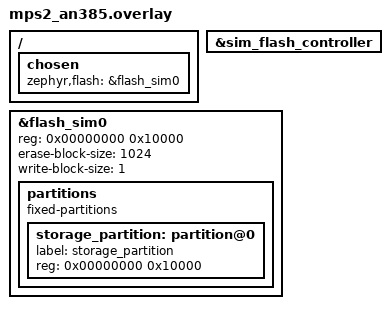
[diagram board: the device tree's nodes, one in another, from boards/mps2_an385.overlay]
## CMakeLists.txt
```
# Zephyr CMakeLists.txt for littlefs ztest
cmake_minimum_required(VERSION 3.20.0)
find_package(Zephyr REQUIRED HINTS $ENV{ZEPHYR_BASE})
project(littlefs_test)

# littlefs core library
target_sources(app PRIVATE
    ../lfs.c
    ../lfs_util.c
)

# Zephyr flash block device wrapper
target_sources(app PRIVATE
    src/lfs_test_bd_zephyr.c
)

# Test sources
target_sources(app PRIVATE
    src/main.c
    src/test_superblocks.c
    src/test_files.c
    src/test_dirs.c
    src/test_paths.c
    src/test_seek.c
    src/test_move.c
    src/test_truncate.c
    src/test_alloc.c
    src/test_attrs.c
    src/test_entries.c
)

target_include_directories(app PRIVATE
    ${CMAKE_CURRENT_SOURCE_DIR}/..
    ${CMAKE_CURRENT_SOURCE_DIR}/../test
)

# Disable littlefs assertions for ztest (they cause kernel panics)
# Use zassert instead for test assertions
target_compile_definitions(app PRIVATE
    LFS_NO_ASSERT
)
```

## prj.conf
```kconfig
# Ztest framework
CONFIG_ZTEST=y

# Size optimization
CONFIG_SIZE_OPTIMIZATIONS=y
CONFIG_LOG=n

# Flash subsystem
CONFIG_FLASH=y
CONFIG_FLASH_SIMULATOR=y
CONFIG_FLASH_SIMULATOR_DOUBLE_WRITES=y
CONFIG_FLASH_SIMULATOR_STATS=n

# Memory (increased for full test suite)
CONFIG_HEAP_MEM_POOL_SIZE=32768
CONFIG_MAIN_STACK_SIZE=8192
```

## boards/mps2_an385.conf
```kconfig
# Board-specific configuration for mps2_an385
# Increase code partition to 512KB
CONFIG_FLASH_SIZE=512
```

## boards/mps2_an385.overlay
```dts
/*
 * Flash simulator overlay for MPS2_AN385
 * Uses the built-in flash simulator for littlefs testing
 */

/ {
	chosen {
		/* Point to simulated flash instead of main flash */
		zephyr,flash = &flash_sim0;
	};
};

/* Enable the flash controller */
&sim_flash_controller {
	status = "okay";
};

/* Override flash_sim0 to have more blocks for testing */
&flash_sim0 {
	status = "okay";
	reg = <0x00000000 0x10000>;  /* 64KB simulated flash */
	erase-block-size = <1024>;
	write-block-size = <1>;

	partitions {
		compatible = "fixed-partitions";
		#address-cells = <1>;
		#size-cells = <1>;

		storage_partition: partition@0 {
			label = "storage_partition";
			reg = <0x00000000 0x10000>;
		};
	};
};
```

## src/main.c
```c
/*
 * littlefs ztest - Block device tests
 *
 * These tests validate that the underlying block device is working correctly.
 * Note: We use 251, a prime, to avoid aliasing powers of 2.
 */
#define LFS_TEST_ZTEST

#include <zephyr/ztest.h>
#include <stdbool.h>
#include <string.h>

#include "lfs.h"
#include "test/lfs_test_bd.h"

/* Shared globals for all test suites */
struct lfs_test_bd ztest_bd;
struct lfs_config ztest_cfg;
bool ztest_bd_initialized = false;

/* Local aliases for bd_tests */
#define bd ztest_bd
#define cfg ztest_cfg

static void *bd_suite_setup(void)
{
    int ret = lfs_test_bd_create(&bd, &cfg, &lfs_test_geometries[0]);
    zassert_equal(ret, 0, "Failed to create block device");
    return NULL;
}

static void bd_suite_teardown(void *f)
{
    ARG_UNUSED(f);
    lfs_test_bd_destroy(&bd, &cfg);
}

static void bd_before_each(void *f)
{
    ARG_UNUSED(f);
    /* Erase entire device before each test for clean state */
    for (lfs_block_t i = 0; i < cfg.block_count; i++) {
        int ret = cfg.erase(&cfg, i);
        zassert_equal(ret, 0, "Failed to erase block %u", i);
    }
}

ZTEST_SUITE(bd_tests, NULL, bd_suite_setup, bd_before_each, NULL, bd_suite_teardown);

/*
 * Test: Write and read a single block
 */
ZTEST(bd_tests, test_one_block)
{
    lfs_size_t read_size = cfg.read_size;
    lfs_size_t prog_size = cfg.prog_size;
    uint8_t buffer[prog_size > read_size ? prog_size : read_size];

    /* Write data */
    zassert_equal(cfg.erase(&cfg, 0), 0, "Erase failed");
    for (lfs_off_t i = 0; i < cfg.block_size; i += prog_size) {
        for (lfs_off_t j = 0; j < prog_size; j++) {
            buffer[j] = (i + j) % 251;
        }
        zassert_equal(cfg.prog(&cfg, 0, i, buffer, prog_size), 0,
                      "Prog failed at offset %u", i);
    }

    /* Read data */
    for (lfs_off_t i = 0; i < cfg.block_size; i += read_size) {
        zassert_equal(cfg.read(&cfg, 0, i, buffer, read_size), 0,
                      "Read failed at offset %u", i);
        for (lfs_off_t j = 0; j < read_size; j++) {
            zassert_equal(buffer[j], (i + j) % 251,
                          "Mismatch at offset %u", i + j);
        }
    }
}

/*
 * Test: Write and read two blocks, verify no interference
 */
ZTEST(bd_tests, test_two_block)
{
    lfs_size_t read_size = cfg.read_size;
    lfs_size_t prog_size = cfg.prog_size;
    uint8_t buffer[prog_size > read_size ? prog_size : read_size];
    lfs_block_t block;

    /* Write block 0 */
    block = 0;
    zassert_equal(cfg.erase(&cfg, block), 0, "Erase failed");
    for (lfs_off_t i = 0; i < cfg.block_size; i += prog_size) {
        for (lfs_off_t j = 0; j < prog_size; j++) {
            buffer[j] = (block + i + j) % 251;
        }
        zassert_equal(cfg.prog(&cfg, block, i, buffer, prog_size), 0,
                      "Prog failed");
    }

    /* Read block 0 */
    for (lfs_off_t i = 0; i < cfg.block_size; i += read_size) {
        zassert_equal(cfg.read(&cfg, block, i, buffer, read_size), 0,
                      "Read failed");
        for (lfs_off_t j = 0; j < read_size; j++) {
            zassert_equal(buffer[j], (block + i + j) % 251,
                          "Mismatch at offset %u", i + j);
        }
    }

    /* Write block 1 */
    block = 1;
    zassert_equal(cfg.erase(&cfg, block), 0, "Erase failed");
    for (lfs_off_t i = 0; i < cfg.block_size; i += prog_size) {
        for (lfs_off_t j = 0; j < prog_size; j++) {
            buffer[j] = (block + i + j) % 251;
        }
        zassert_equal(cfg.prog(&cfg, block, i, buffer, prog_size), 0,
                      "Prog failed");
    }

    /* Read block 1 */
    for (lfs_off_t i = 0; i < cfg.block_size; i += read_size) {
        zassert_equal(cfg.read(&cfg, block, i, buffer, read_size), 0,
                      "Read failed");
        for (lfs_off_t j = 0; j < read_size; j++) {
            zassert_equal(buffer[j], (block + i + j) % 251,
                          "Mismatch at offset %u", i + j);
        }
    }

    /* Read block 0 again - verify not corrupted */
    block = 0;
    for (lfs_off_t i = 0; i < cfg.block_size; i += read_size) {
        zassert_equal(cfg.read(&cfg, block, i, buffer, read_size), 0,
                      "Read failed");
        for (lfs_off_t j = 0; j < read_size; j++) {
            zassert_equal(buffer[j], (block + i + j) % 251,
                          "Block 0 was corrupted");
        }
    }
}

/*
 * Test: Write first and last blocks
 */
ZTEST(bd_tests, test_last_block)
{
    lfs_size_t read_size = cfg.read_size;
    lfs_size_t prog_size = cfg.prog_size;
    uint8_t buffer[prog_size > read_size ? prog_size : read_size];
    lfs_block_t block;

    /* Write block 0 */
    block = 0;
    zassert_equal(cfg.erase(&cfg, block), 0, "Erase failed");
    for (lfs_off_t i = 0; i < cfg.block_size; i += prog_size) {
        for (lfs_off_t j = 0; j < prog_size; j++) {
            buffer[j] = (block + i + j) % 251;
        }
        zassert_equal(cfg.prog(&cfg, block, i, buffer, prog_size), 0,
                      "Prog failed");
    }

    /* Write block n-1 */
    block = cfg.block_count - 1;
    zassert_equal(cfg.erase(&cfg, block), 0, "Erase failed");
    for (lfs_off_t i = 0; i < cfg.block_size; i += prog_size) {
        for (lfs_off_t j = 0; j < prog_size; j++) {
            buffer[j] = (block + i + j) % 251;
        }
        zassert_equal(cfg.prog(&cfg, block, i, buffer, prog_size), 0,
                      "Prog failed");
    }

    /* Read block 0 */
    block = 0;
    for (lfs_off_t i = 0; i < cfg.block_size; i += read_size) {
        zassert_equal(cfg.read(&cfg, block, i, buffer, read_size), 0,
                      "Read failed");
        for (lfs_off_t j = 0; j < read_size; j++) {
            zassert_equal(buffer[j], (block + i + j) % 251,
                          "Mismatch");
        }
    }

    /* Read block n-1 */
    block = cfg.block_count - 1;
    for (lfs_off_t i = 0; i < cfg.block_size; i += read_size) {
        zassert_equal(cfg.read(&cfg, block, i, buffer, read_size), 0,
                      "Read failed");
        for (lfs_off_t j = 0; j < read_size; j++) {
            zassert_equal(buffer[j], (block + i + j) % 251,
                          "Mismatch");
        }
    }
}

/*
 * Test: Write and read blocks at powers of two
 */
ZTEST(bd_tests, test_powers_of_two)
{
    lfs_size_t read_size = cfg.read_size;
    lfs_size_t prog_size = cfg.prog_size;
    uint8_t buffer[prog_size > read_size ? prog_size : read_size];

    /* Write/read every power of 2 */
    lfs_block_t block = 1;
    while (block < cfg.block_count) {
        /* Write */
        zassert_equal(cfg.erase(&cfg, block), 0, "Erase failed");
        for (lfs_off_t i = 0; i < cfg.block_size; i += prog_size) {
            for (lfs_off_t j = 0; j < prog_size; j++) {
                buffer[j] = (block + i + j) % 251;
            }
            zassert_equal(cfg.prog(&cfg, block, i, buffer, prog_size), 0,
                          "Prog failed");
        }

        /* Read */
        for (lfs_off_t i = 0; i < cfg.block_size; i += read_size) {
            zassert_equal(cfg.read(&cfg, block, i, buffer, read_size), 0,
                          "Read failed");
            for (lfs_off_t j = 0; j < read_size; j++) {
                zassert_equal(buffer[j], (block + i + j) % 251,
                              "Mismatch at block %u", block);
            }
        }

        block *= 2;
    }
}

/*
 * Test: Write and read blocks at Fibonacci numbers
 */
ZTEST(bd_tests, test_fibonacci)
{
    lfs_size_t read_size = cfg.read_size;
    lfs_size_t prog_size = cfg.prog_size;
    uint8_t buffer[prog_size > read_size ? prog_size : read_size];

    /* Write/read every Fibonacci number */
    lfs_block_t block = 1;
    lfs_block_t block_prev = 1;
    while (block < cfg.block_count) {
        /* Write */
        zassert_equal(cfg.erase(&cfg, block), 0, "Erase failed");
        for (lfs_off_t i = 0; i < cfg.block_size; i += prog_size) {
            for (lfs_off_t j = 0; j < prog_size; j++) {
                buffer[j] = (block + i + j) % 251;
            }
            zassert_equal(cfg.prog(&cfg, block, i, buffer, prog_size), 0,
                          "Prog failed");
        }

        /* Read */
        for (lfs_off_t i = 0; i < cfg.block_size; i += read_size) {
            zassert_equal(cfg.read(&cfg, block, i, buffer, read_size), 0,
                          "Read failed");
            for (lfs_off_t j = 0; j < read_size; j++) {
                zassert_equal(buffer[j], (block + i + j) % 251,
                              "Mismatch at block %u", block);
            }
        }

        lfs_block_t next = block + block_prev;
        block_prev = block;
        block = next;
    }
}
```

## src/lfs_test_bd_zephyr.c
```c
/*
 * Block device implementation using Zephyr flash API
 */
#define LFS_TEST_ZTEST

#include <zephyr/kernel.h>
#include <zephyr/device.h>
#include <zephyr/drivers/flash.h>
#include <string.h>

#include "lfs.h"
#include "test/lfs_test_bd.h"

/* Standard geometries - use smaller values for constrained memory
 * qemu_cortex_m3 has 256KB flash, we use a portion of it
 */
const struct lfs_test_geometry lfs_test_geometries[] = {
    /* 1KB erase size, 64 blocks = 64KB total (MPS2 flash simulator) */
    {"qemu", 1, 1, 1024, 64},
};

const size_t lfs_test_geometry_count =
    sizeof(lfs_test_geometries) / sizeof(lfs_test_geometries[0]);

static int zephyr_read(const struct lfs_config *c, lfs_block_t block,
                       lfs_off_t off, void *buffer, lfs_size_t size) {
    struct lfs_test_bd *bd = c->context;
    off_t addr = bd->offset + block * c->block_size + off;

    int ret = flash_read(bd->flash_dev, addr, buffer, size);
    return ret < 0 ? LFS_ERR_IO : 0;
}

static int zephyr_prog(const struct lfs_config *c, lfs_block_t block,
                       lfs_off_t off, const void *buffer, lfs_size_t size) {
    struct lfs_test_bd *bd = c->context;
    off_t addr = bd->offset + block * c->block_size + off;

    int ret = flash_write(bd->flash_dev, addr, buffer, size);
    return ret < 0 ? LFS_ERR_IO : 0;
}

static int zephyr_erase(const struct lfs_config *c, lfs_block_t block) {
    struct lfs_test_bd *bd = c->context;
    off_t addr = bd->offset + block * c->block_size;

    int ret = flash_erase(bd->flash_dev, addr, c->block_size);
    return ret < 0 ? LFS_ERR_IO : 0;
}

static int zephyr_sync(const struct lfs_config *c) {
    ARG_UNUSED(c);
    return 0;
}

int lfs_test_bd_create(struct lfs_test_bd *bd,
                       struct lfs_config *cfg,
                       const struct lfs_test_geometry *geom) {
    memset(bd, 0, sizeof(*bd));

    /* Use simulated flash controller device */
    bd->flash_dev = DEVICE_DT_GET(DT_CHOSEN(zephyr_flash_controller));
    bd->offset = 0;  /* Simulated flash - full device available */
    bd->size = geom->erase_size * geom->erase_count;

    if (!device_is_ready(bd->flash_dev)) {
        return LFS_ERR_IO;
    }

    /* Initialize lfs config */
    memset(cfg, 0, sizeof(*cfg));
    cfg->context = bd;
    cfg->read = zephyr_read;
    cfg->prog = zephyr_prog;
    cfg->erase = zephyr_erase;
    cfg->sync = zephyr_sync;
    cfg->read_size = geom->read_size;
    cfg->prog_size = geom->prog_size;
    cfg->block_size = geom->erase_size;
    cfg->block_count = geom->erase_count;
    cfg->block_cycles = -1;
    cfg->cache_size = 64;
    cfg->lookahead_size = 16;

    return 0;
}

int lfs_test_bd_destroy(struct lfs_test_bd *bd,
                        struct lfs_config *cfg) {
    ARG_UNUSED(bd);
    ARG_UNUSED(cfg);
    return 0;
}
```

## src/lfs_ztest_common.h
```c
/*
 * Common test infrastructure for littlefs ztest
 */
#ifndef LFS_ZTEST_COMMON_H
#define LFS_ZTEST_COMMON_H

#include <zephyr/ztest.h>
#include <string.h>

#include "lfs.h"
#include "test/lfs_test_bd.h"

/* Shared block device and config */
extern struct lfs_test_bd ztest_bd;
extern struct lfs_config ztest_cfg;
extern bool ztest_bd_initialized;

/* Initialize the block device if not already done */
static inline void lfs_ztest_init_device(void)
{
    if (!ztest_bd_initialized) {
        int ret = lfs_test_bd_create(&ztest_bd, &ztest_cfg, &lfs_test_geometries[0]);
        zassert_equal(ret, 0, "Failed to create block device");
        ztest_bd_initialized = true;
    }
}

/* Helper to erase the filesystem before test */
static inline void lfs_ztest_format_device(void)
{
    lfs_ztest_init_device();
    /* Erase entire device for clean state */
    for (lfs_block_t i = 0; i < ztest_cfg.block_count; i++) {
        int ret = ztest_cfg.erase(&ztest_cfg, i);
        zassert_equal(ret, 0, "Failed to erase block %u", i);
    }
}

/* Simple PRNG for test data generation */
static inline uint32_t lfs_ztest_prng(uint32_t *state)
{
    *state = *state * 1103515245 + 12345;
    return *state;
}

#endif /* LFS_ZTEST_COMMON_H */
```

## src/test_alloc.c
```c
/*
 * Block allocation tests
 */
#include "lfs_ztest_common.h"
#include <stdio.h>

static void *alloc_setup(void)
{
    lfs_ztest_format_device();
    return NULL;
}

static void alloc_before(void *f)
{
    ARG_UNUSED(f);
    lfs_ztest_format_device();
}

ZTEST_SUITE(alloc_tests, NULL, alloc_setup, alloc_before, NULL, NULL);

/* Parallel allocation - create many files without closing */
ZTEST(alloc_tests, test_parallel_alloc)
{
    lfs_t lfs;
    zassert_equal(lfs_format(&lfs, &ztest_cfg), 0, "Format failed");
    zassert_equal(lfs_mount(&lfs, &ztest_cfg), 0, "Mount failed");

    const int N = 3;  /* Limited by open file handles */
    lfs_file_t files[3];

    /* Open multiple files at once */
    for (int i = 0; i < N; i++) {
        char name[32];
        snprintf(name, sizeof(name), "parallel%d", i);
        zassert_equal(lfs_file_open(&lfs, &files[i], name,
                LFS_O_WRONLY | LFS_O_CREAT | LFS_O_EXCL), 0,
                "Open %d failed", i);
    }

    /* Write to all of them */
    for (int i = 0; i < N; i++) {
        char data[32];
        snprintf(data, sizeof(data), "data%d", i);
        zassert_equal(lfs_file_write(&lfs, &files[i], data, strlen(data)),
                      (lfs_ssize_t)strlen(data), "Write %d failed", i);
    }

    /* Close all */
    for (int i = 0; i < N; i++) {
        zassert_equal(lfs_file_close(&lfs, &files[i]), 0, "Close %d failed", i);
    }

    zassert_equal(lfs_unmount(&lfs), 0, "Unmount failed");

    /* Verify */
    zassert_equal(lfs_mount(&lfs, &ztest_cfg), 0, "Remount failed");
    for (int i = 0; i < N; i++) {
        char name[32], expected[32], buffer[32];
        snprintf(name, sizeof(name), "parallel%d", i);
        snprintf(expected, sizeof(expected), "data%d", i);
        lfs_file_t file;
        zassert_equal(lfs_file_open(&lfs, &file, name, LFS_O_RDONLY), 0,
                      "Reopen %d failed", i);
        int len = lfs_file_read(&lfs, &file, buffer, sizeof(buffer));
        zassert_equal(len, (int)strlen(expected), "Read %d size wrong", i);
        buffer[len] = '\0';
        zassert_equal(strcmp(buffer, expected), 0, "Data %d mismatch", i);
        zassert_equal(lfs_file_close(&lfs, &file), 0, "Close %d failed", i);
    }
    zassert_equal(lfs_unmount(&lfs), 0, "Unmount failed");
}

/* Serial allocation - create and close files sequentially */
ZTEST(alloc_tests, test_serial_alloc)
{
    lfs_t lfs;
    zassert_equal(lfs_format(&lfs, &ztest_cfg), 0, "Format failed");
    zassert_equal(lfs_mount(&lfs, &ztest_cfg), 0, "Mount failed");

    const int N = 10;
    for (int i = 0; i < N; i++) {
        char name[32], data[32];
        snprintf(name, sizeof(name), "serial%d", i);
        snprintf(data, sizeof(data), "serial_data_%d", i);

        lfs_file_t file;
        zassert_equal(lfs_file_open(&lfs, &file, name,
                LFS_O_WRONLY | LFS_O_CREAT | LFS_O_EXCL), 0,
                "Open %d failed", i);
        zassert_equal(lfs_file_write(&lfs, &file, data, strlen(data)),
                      (lfs_ssize_t)strlen(data), "Write %d failed", i);
        zassert_equal(lfs_file_close(&lfs, &file), 0, "Close %d failed", i);
    }

    zassert_equal(lfs_unmount(&lfs), 0, "Unmount failed");

    /* Verify */
    zassert_equal(lfs_mount(&lfs, &ztest_cfg), 0, "Remount failed");
    for (int i = 0; i < N; i++) {
        char name[32], expected[32], buffer[64];
        snprintf(name, sizeof(name), "serial%d", i);
        snprintf(expected, sizeof(expected), "serial_data_%d", i);

        lfs_file_t file;
        zassert_equal(lfs_file_open(&lfs, &file, name, LFS_O_RDONLY), 0,
                      "Reopen %d failed", i);
        int len = lfs_file_read(&lfs, &file, buffer, sizeof(buffer));
        zassert_equal(len, (int)strlen(expected), "Read %d size wrong", i);
        buffer[len] = '\0';
        zassert_equal(strcmp(buffer, expected), 0, "Data %d mismatch", i);
        zassert_equal(lfs_file_close(&lfs, &file), 0, "Close %d failed", i);
    }
    zassert_equal(lfs_unmount(&lfs), 0, "Unmount failed");
}

/*
 * NOTE: Exhaustion test removed - the Zephyr flash simulator hits internal
 * assertions when trying to fill the filesystem completely. This test
 * requires the emubd which tracks wear properly. Test coverage for
 * exhaustion is provided by gtest with emubd.
 */
```

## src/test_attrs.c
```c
/*
 * Extended attributes tests
 */
#include "lfs_ztest_common.h"

static void *attrs_setup(void)
{
    lfs_ztest_format_device();
    return NULL;
}

static void attrs_before(void *f)
{
    ARG_UNUSED(f);
    lfs_ztest_format_device();
}

ZTEST_SUITE(attrs_tests, NULL, attrs_setup, attrs_before, NULL, NULL);

/* Get/set attributes */
ZTEST(attrs_tests, test_getset)
{
    lfs_t lfs;
    zassert_equal(lfs_format(&lfs, &ztest_cfg), 0, "Format failed");
    zassert_equal(lfs_mount(&lfs, &ztest_cfg), 0, "Mount failed");

    /* Create a file */
    lfs_file_t file;
    zassert_equal(lfs_file_open(&lfs, &file, "attrfile",
            LFS_O_WRONLY | LFS_O_CREAT | LFS_O_EXCL), 0, "Open failed");
    zassert_equal(lfs_file_write(&lfs, &file, "test", 4), 4, "Write failed");
    zassert_equal(lfs_file_close(&lfs, &file), 0, "Close failed");

    /* Set attribute */
    const char *attrdata = "myattr";
    zassert_equal(lfs_setattr(&lfs, "attrfile", 'A', attrdata, strlen(attrdata)), 0,
                  "Setattr failed");

    /* Get attribute */
    char buffer[32];
    lfs_ssize_t len = lfs_getattr(&lfs, "attrfile", 'A', buffer, sizeof(buffer));
    zassert_equal(len, (lfs_ssize_t)strlen(attrdata), "Getattr size wrong");
    zassert_equal(memcmp(buffer, attrdata, len), 0, "Attr data mismatch");

    zassert_equal(lfs_unmount(&lfs), 0, "Unmount failed");

    /* Verify persists across mount */
    zassert_equal(lfs_mount(&lfs, &ztest_cfg), 0, "Remount failed");
    len = lfs_getattr(&lfs, "attrfile", 'A', buffer, sizeof(buffer));
    zassert_equal(len, (lfs_ssize_t)strlen(attrdata), "Getattr2 size wrong");
    zassert_equal(memcmp(buffer, attrdata, len), 0, "Attr2 data mismatch");
    zassert_equal(lfs_unmount(&lfs), 0, "Unmount failed");
}

/* Root attributes */
ZTEST(attrs_tests, test_root_attrs)
{
    lfs_t lfs;
    zassert_equal(lfs_format(&lfs, &ztest_cfg), 0, "Format failed");
    zassert_equal(lfs_mount(&lfs, &ztest_cfg), 0, "Mount failed");

    /* Set attribute on root */
    const char *rootattr = "rootdata";
    zassert_equal(lfs_setattr(&lfs, "/", 'R', rootattr, strlen(rootattr)), 0,
                  "Setattr root failed");

    /* Get it back */
    char buffer[32];
    lfs_ssize_t len = lfs_getattr(&lfs, "/", 'R', buffer, sizeof(buffer));
    zassert_equal(len, (lfs_ssize_t)strlen(rootattr), "Getattr size wrong");
    zassert_equal(memcmp(buffer, rootattr, len), 0, "Root attr mismatch");

    /* Also try "." */
    len = lfs_getattr(&lfs, ".", 'R', buffer, sizeof(buffer));
    zassert_equal(len, (lfs_ssize_t)strlen(rootattr), "Getattr . size wrong");

    zassert_equal(lfs_unmount(&lfs), 0, "Unmount failed");
}

/* File config with attributes */
ZTEST(attrs_tests, test_file_config)
{
    lfs_t lfs;
    zassert_equal(lfs_format(&lfs, &ztest_cfg), 0, "Format failed");
    zassert_equal(lfs_mount(&lfs, &ztest_cfg), 0, "Mount failed");

    /* Open file with attribute in config */
    uint8_t attr_buffer[64];
    memset(attr_buffer, 0, sizeof(attr_buffer));
    strcpy((char *)attr_buffer, "file_attr");

    struct lfs_attr attrs[] = {
        {.type = 'T', .buffer = attr_buffer, .size = 9}
    };
    struct lfs_file_config cfg = {
        .attrs = attrs,
        .attr_count = 1,
    };

    lfs_file_t file;
    zassert_equal(lfs_file_opencfg(&lfs, &file, "cfgfile",
            LFS_O_WRONLY | LFS_O_CREAT | LFS_O_EXCL, &cfg), 0, "Open failed");
    zassert_equal(lfs_file_write(&lfs, &file, "hello", 5), 5, "Write failed");
    zassert_equal(lfs_file_close(&lfs, &file), 0, "Close failed");

    /* Read attribute back */
    char buffer[32];
    lfs_ssize_t len = lfs_getattr(&lfs, "cfgfile", 'T', buffer, sizeof(buffer));
    zassert_equal(len, 9, "Attr size wrong");
    zassert_equal(memcmp(buffer, "file_attr", 9), 0, "Attr mismatch");

    zassert_equal(lfs_unmount(&lfs), 0, "Unmount failed");
}

/* Remove attribute */
ZTEST(attrs_tests, test_remove_attr)
{
    lfs_t lfs;
    zassert_equal(lfs_format(&lfs, &ztest_cfg), 0, "Format failed");
    zassert_equal(lfs_mount(&lfs, &ztest_cfg), 0, "Mount failed");

    /* Create file and set attr */
    lfs_file_t file;
    zassert_equal(lfs_file_open(&lfs, &file, "rmattr",
            LFS_O_WRONLY | LFS_O_CREAT | LFS_O_EXCL), 0, "Open failed");
    zassert_equal(lfs_file_close(&lfs, &file), 0, "Close failed");

    zassert_equal(lfs_setattr(&lfs, "rmattr", 'X', "toremove", 8), 0,
                  "Setattr failed");

    /* Verify it exists */
    char buffer[32];
    zassert_equal(lfs_getattr(&lfs, "rmattr", 'X', buffer, sizeof(buffer)), 8,
                  "Getattr failed");

    /* Remove by setting size 0 */
    zassert_equal(lfs_removeattr(&lfs, "rmattr", 'X'), 0, "Removeattr failed");

    /* Verify gone */
    zassert_equal(lfs_getattr(&lfs, "rmattr", 'X', buffer, sizeof(buffer)),
                  LFS_ERR_NOATTR, "Should be gone");

    zassert_equal(lfs_unmount(&lfs), 0, "Unmount failed");
}
```

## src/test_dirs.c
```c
/*
 * Directory operation tests - creation, removal, rename, listing
 */
#include "lfs_ztest_common.h"
#include <stdio.h>

static void *dirs_setup(void)
{
    lfs_ztest_format_device();
    return NULL;
}

static void dirs_before(void *f)
{
    ARG_UNUSED(f);
    lfs_ztest_format_device();
}

ZTEST_SUITE(dirs_tests, NULL, dirs_setup, dirs_before, NULL, NULL);

/* Test root directory */
ZTEST(dirs_tests, test_root)
{
    lfs_t lfs;
    zassert_equal(lfs_format(&lfs, &ztest_cfg), 0, "Format failed");
    zassert_equal(lfs_mount(&lfs, &ztest_cfg), 0, "Mount failed");

    lfs_dir_t dir;
    zassert_equal(lfs_dir_open(&lfs, &dir, "/"), 0, "Open root failed");

    struct lfs_info info;
    zassert_equal(lfs_dir_read(&lfs, &dir, &info), 1, "Read . failed");
    zassert_equal(info.type, LFS_TYPE_DIR, ". not a dir");
    zassert_equal(strcmp(info.name, "."), 0, ". name wrong");

    zassert_equal(lfs_dir_read(&lfs, &dir, &info), 1, "Read .. failed");
    zassert_equal(info.type, LFS_TYPE_DIR, ".. not a dir");
    zassert_equal(strcmp(info.name, ".."), 0, ".. name wrong");

    zassert_equal(lfs_dir_read(&lfs, &dir, &info), 0, "Should be empty");
    zassert_equal(lfs_dir_close(&lfs, &dir), 0, "Close failed");
    zassert_equal(lfs_unmount(&lfs), 0, "Unmount failed");
}

/* Many directory creation */
ZTEST(dirs_tests, test_many_creation)
{
    lfs_t lfs;
    zassert_equal(lfs_format(&lfs, &ztest_cfg), 0, "Format failed");
    zassert_equal(lfs_mount(&lfs, &ztest_cfg), 0, "Mount failed");

    const int N = 10;
    for (int i = 0; i < N; i++) {
        char path[64];
        snprintf(path, sizeof(path), "dir%03d", i);
        zassert_equal(lfs_mkdir(&lfs, path), 0, "Mkdir %s failed", path);
    }
    zassert_equal(lfs_unmount(&lfs), 0, "Unmount failed");

    /* Verify directories exist */
    zassert_equal(lfs_mount(&lfs, &ztest_cfg), 0, "Remount failed");
    lfs_dir_t dir;
    zassert_equal(lfs_dir_open(&lfs, &dir, "/"), 0, "Open root failed");

    struct lfs_info info;
    zassert_equal(lfs_dir_read(&lfs, &dir, &info), 1, "Read . failed");
    zassert_equal(lfs_dir_read(&lfs, &dir, &info), 1, "Read .. failed");

    for (int i = 0; i < N; i++) {
        char path[64];
        snprintf(path, sizeof(path), "dir%03d", i);
        zassert_equal(lfs_dir_read(&lfs, &dir, &info), 1, "Read %s failed", path);
        zassert_equal(info.type, LFS_TYPE_DIR, "%s not a dir", path);
        zassert_equal(strcmp(info.name, path), 0, "%s name wrong", path);
    }
    zassert_equal(lfs_dir_read(&lfs, &dir, &info), 0, "Extra entries");
    zassert_equal(lfs_dir_close(&lfs, &dir), 0, "Close failed");
    zassert_equal(lfs_unmount(&lfs), 0, "Unmount failed");
}

/* Directory removal */
ZTEST(dirs_tests, test_many_removal)
{
    lfs_t lfs;
    zassert_equal(lfs_format(&lfs, &ztest_cfg), 0, "Format failed");
    zassert_equal(lfs_mount(&lfs, &ztest_cfg), 0, "Mount failed");

    const int N = 5;
    for (int i = 0; i < N; i++) {
        char path[64];
        snprintf(path, sizeof(path), "removeme%03d", i);
        zassert_equal(lfs_mkdir(&lfs, path), 0, "Mkdir %s failed", path);
    }
    zassert_equal(lfs_unmount(&lfs), 0, "Unmount failed");

    /* Remove all directories */
    zassert_equal(lfs_mount(&lfs, &ztest_cfg), 0, "Remount failed");
    for (int i = 0; i < N; i++) {
        char path[64];
        snprintf(path, sizeof(path), "removeme%03d", i);
        zassert_equal(lfs_remove(&lfs, path), 0, "Remove %s failed", path);
    }
    zassert_equal(lfs_unmount(&lfs), 0, "Unmount failed");

    /* Verify empty */
    zassert_equal(lfs_mount(&lfs, &ztest_cfg), 0, "Remount2 failed");
    lfs_dir_t dir;
    zassert_equal(lfs_dir_open(&lfs, &dir, "/"), 0, "Open root failed");
    struct lfs_info info;
    zassert_equal(lfs_dir_read(&lfs, &dir, &info), 1, "Read . failed");
    zassert_equal(lfs_dir_read(&lfs, &dir, &info), 1, "Read .. failed");
    zassert_equal(lfs_dir_read(&lfs, &dir, &info), 0, "Should be empty");
    zassert_equal(lfs_dir_close(&lfs, &dir), 0, "Close failed");
    zassert_equal(lfs_unmount(&lfs), 0, "Unmount failed");
}

/* Directory rename */
ZTEST(dirs_tests, test_many_rename)
{
    lfs_t lfs;
    zassert_equal(lfs_format(&lfs, &ztest_cfg), 0, "Format failed");
    zassert_equal(lfs_mount(&lfs, &ztest_cfg), 0, "Mount failed");

    const int N = 5;
    for (int i = 0; i < N; i++) {
        char path[64];
        snprintf(path, sizeof(path), "test%03d", i);
        zassert_equal(lfs_mkdir(&lfs, path), 0, "Mkdir %s failed", path);
    }
    zassert_equal(lfs_unmount(&lfs), 0, "Unmount failed");

    /* Rename all directories */
    zassert_equal(lfs_mount(&lfs, &ztest_cfg), 0, "Remount failed");
    for (int i = 0; i < N; i++) {
        char oldpath[64], newpath[64];
        snprintf(oldpath, sizeof(oldpath), "test%03d", i);
        snprintf(newpath, sizeof(newpath), "tedd%03d", i);
        zassert_equal(lfs_rename(&lfs, oldpath, newpath), 0,
                      "Rename %s->%s failed", oldpath, newpath);
    }
    zassert_equal(lfs_unmount(&lfs), 0, "Unmount failed");

    /* Verify renamed */
    zassert_equal(lfs_mount(&lfs, &ztest_cfg), 0, "Remount2 failed");
    for (int i = 0; i < N; i++) {
        char path[64];
        struct lfs_info info;
        snprintf(path, sizeof(path), "tedd%03d", i);
        zassert_equal(lfs_stat(&lfs, path, &info), 0, "Stat %s failed", path);
        zassert_equal(info.type, LFS_TYPE_DIR, "%s not a dir", path);
    }
    zassert_equal(lfs_unmount(&lfs), 0, "Unmount failed");
}

/* File creation in directories */
ZTEST(dirs_tests, test_file_creation)
{
    lfs_t lfs;
    zassert_equal(lfs_format(&lfs, &ztest_cfg), 0, "Format failed");
    zassert_equal(lfs_mount(&lfs, &ztest_cfg), 0, "Mount failed");

    const int N = 5;
    for (int i = 0; i < N; i++) {
        char path[64];
        snprintf(path, sizeof(path), "file%03d", i);
        lfs_file_t file;
        zassert_equal(lfs_file_open(&lfs, &file, path,
                LFS_O_WRONLY | LFS_O_CREAT | LFS_O_EXCL), 0,
                "Create %s failed", path);
        zassert_equal(lfs_file_close(&lfs, &file), 0, "Close %s failed", path);
    }
    zassert_equal(lfs_unmount(&lfs), 0, "Unmount failed");

    /* Verify files */
    zassert_equal(lfs_mount(&lfs, &ztest_cfg), 0, "Remount failed");
    lfs_dir_t dir;
    zassert_equal(lfs_dir_open(&lfs, &dir, "/"), 0, "Open root failed");
    struct lfs_info info;
    zassert_equal(lfs_dir_read(&lfs, &dir, &info), 1, "Read . failed");
    zassert_equal(lfs_dir_read(&lfs, &dir, &info), 1, "Read .. failed");
    for (int i = 0; i < N; i++) {
        char path[64];
        snprintf(path, sizeof(path), "file%03d", i);
        zassert_equal(lfs_dir_read(&lfs, &dir, &info), 1, "Read %s failed", path);
        zassert_equal(info.type, LFS_TYPE_REG, "%s not a file", path);
        zassert_equal(strcmp(info.name, path), 0, "%s name wrong", path);
    }
    zassert_equal(lfs_dir_read(&lfs, &dir, &info), 0, "Extra entries");
    zassert_equal(lfs_dir_close(&lfs, &dir), 0, "Close failed");
    zassert_equal(lfs_unmount(&lfs), 0, "Unmount failed");
}

/* Nested directories */
ZTEST(dirs_tests, test_nested)
{
    lfs_t lfs;
    zassert_equal(lfs_format(&lfs, &ztest_cfg), 0, "Format failed");
    zassert_equal(lfs_mount(&lfs, &ztest_cfg), 0, "Mount failed");

    zassert_equal(lfs_mkdir(&lfs, "a"), 0, "mkdir a failed");
    zassert_equal(lfs_mkdir(&lfs, "a/b"), 0, "mkdir a/b failed");
    zassert_equal(lfs_mkdir(&lfs, "a/b/c"), 0, "mkdir a/b/c failed");

    /* Create file in nested dir */
    lfs_file_t file;
    zassert_equal(lfs_file_open(&lfs, &file, "a/b/c/deep",
            LFS_O_WRONLY | LFS_O_CREAT | LFS_O_EXCL), 0, "Create failed");
    zassert_equal(lfs_file_write(&lfs, &file, "nested!", 7), 7, "Write failed");
    zassert_equal(lfs_file_close(&lfs, &file), 0, "Close failed");
    zassert_equal(lfs_unmount(&lfs), 0, "Unmount failed");

    /* Verify */
    zassert_equal(lfs_mount(&lfs, &ztest_cfg), 0, "Remount failed");
    struct lfs_info info;
    zassert_equal(lfs_stat(&lfs, "a/b/c/deep", &info), 0, "Stat failed");
    zassert_equal(info.type, LFS_TYPE_REG, "Not a file");
    zassert_equal(info.size, 7, "Size wrong");
    zassert_equal(lfs_unmount(&lfs), 0, "Unmount failed");
}

/* Directory errors */
ZTEST(dirs_tests, test_errors)
{
    lfs_t lfs;
    zassert_equal(lfs_format(&lfs, &ztest_cfg), 0, "Format failed");
    zassert_equal(lfs_mount(&lfs, &ztest_cfg), 0, "Mount failed");

    /* Create a directory and file */
    zassert_equal(lfs_mkdir(&lfs, "mydir"), 0, "mkdir failed");
    lfs_file_t file;
    zassert_equal(lfs_file_open(&lfs, &file, "myfile",
            LFS_O_WRONLY | LFS_O_CREAT | LFS_O_EXCL), 0, "Create failed");
    zassert_equal(lfs_file_close(&lfs, &file), 0, "Close failed");

    /* Try to create existing dir */
    zassert_equal(lfs_mkdir(&lfs, "mydir"), LFS_ERR_EXIST, "Should fail");

    /* Try to remove non-empty parent (create file in dir first) */
    zassert_equal(lfs_file_open(&lfs, &file, "mydir/child",
            LFS_O_WRONLY | LFS_O_CREAT | LFS_O_EXCL), 0, "Create child failed");
    zassert_equal(lfs_file_close(&lfs, &file), 0, "Close failed");
    zassert_equal(lfs_remove(&lfs, "mydir"), LFS_ERR_NOTEMPTY, "Should fail");

    /* Try to open file as directory */
    lfs_dir_t dir;
    zassert_equal(lfs_dir_open(&lfs, &dir, "myfile"), LFS_ERR_NOTDIR,
                  "Should fail");

    zassert_equal(lfs_unmount(&lfs), 0, "Unmount failed");
}
```

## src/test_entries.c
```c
/*
 * Inline file entry tests
 */
#include "lfs_ztest_common.h"
#include <stdio.h>

static void *entries_setup(void)
{
    lfs_ztest_format_device();
    return NULL;
}

static void entries_before(void *f)
{
    ARG_UNUSED(f);
    lfs_ztest_format_device();
}

ZTEST_SUITE(entries_tests, NULL, entries_setup, entries_before, NULL, NULL);

/* Test inline file growth */
ZTEST(entries_tests, test_grow)
{
    lfs_t lfs;
    zassert_equal(lfs_format(&lfs, &ztest_cfg), 0, "Format failed");
    zassert_equal(lfs_mount(&lfs, &ztest_cfg), 0, "Mount failed");

    lfs_file_t file;
    zassert_equal(lfs_file_open(&lfs, &file, "grow",
            LFS_O_WRONLY | LFS_O_CREAT | LFS_O_EXCL), 0, "Open failed");

    /* Write small amounts, growing the file */
    for (int i = 0; i < 10; i++) {
        char data[8];
        snprintf(data, sizeof(data), "%d", i);
        zassert_equal(lfs_file_write(&lfs, &file, data, strlen(data)),
                      (lfs_ssize_t)strlen(data), "Write %d failed", i);
        zassert_equal(lfs_file_sync(&lfs, &file), 0, "Sync %d failed", i);
    }
    zassert_equal(lfs_file_close(&lfs, &file), 0, "Close failed");

    /* Verify */
    zassert_equal(lfs_file_open(&lfs, &file, "grow", LFS_O_RDONLY), 0,
                  "Open read failed");
    char buffer[64];
    lfs_ssize_t len = lfs_file_read(&lfs, &file, buffer, sizeof(buffer));
    zassert_true(len > 0, "Read failed");
    buffer[len] = '\0';
    zassert_equal(strcmp(buffer, "0123456789"), 0, "Data mismatch: %s", buffer);
    zassert_equal(lfs_file_close(&lfs, &file), 0, "Close failed");

    zassert_equal(lfs_unmount(&lfs), 0, "Unmount failed");
}

/* Test inline file shrink */
ZTEST(entries_tests, test_shrink)
{
    lfs_t lfs;
    zassert_equal(lfs_format(&lfs, &ztest_cfg), 0, "Format failed");
    zassert_equal(lfs_mount(&lfs, &ztest_cfg), 0, "Mount failed");

    lfs_file_t file;
    zassert_equal(lfs_file_open(&lfs, &file, "shrink",
            LFS_O_WRONLY | LFS_O_CREAT | LFS_O_EXCL), 0, "Open failed");
    zassert_equal(lfs_file_write(&lfs, &file, "0123456789", 10), 10,
                  "Write failed");
    zassert_equal(lfs_file_close(&lfs, &file), 0, "Close failed");

    /* Shrink by truncating */
    zassert_equal(lfs_file_open(&lfs, &file, "shrink", LFS_O_RDWR), 0,
                  "Open RW failed");
    zassert_equal(lfs_file_truncate(&lfs, &file, 5), 0, "Truncate failed");
    zassert_equal(lfs_file_close(&lfs, &file), 0, "Close failed");

    /* Verify */
    char buffer[16];
    zassert_equal(lfs_file_open(&lfs, &file, "shrink", LFS_O_RDONLY), 0,
                  "Open read failed");
    zassert_equal(lfs_file_read(&lfs, &file, buffer, sizeof(buffer)), 5,
                  "Read failed");
    zassert_equal(memcmp(buffer, "01234", 5), 0, "Data mismatch");
    zassert_equal(lfs_file_close(&lfs, &file), 0, "Close failed");

    zassert_equal(lfs_unmount(&lfs), 0, "Unmount failed");
}

/* Test spilling from inline to CTZ */
ZTEST(entries_tests, test_spill)
{
    lfs_t lfs;
    zassert_equal(lfs_format(&lfs, &ztest_cfg), 0, "Format failed");
    zassert_equal(lfs_mount(&lfs, &ztest_cfg), 0, "Mount failed");

    lfs_file_t file;
    zassert_equal(lfs_file_open(&lfs, &file, "spill",
            LFS_O_WRONLY | LFS_O_CREAT | LFS_O_EXCL), 0, "Open failed");

    /* Write data that will exceed inline limit and spill to blocks */
    uint8_t buffer[256];
    uint32_t prng = 42;
    lfs_size_t total = 0;
    lfs_size_t target = 2048;  /* Large enough to spill */

    while (total < target) {
        lfs_size_t chunk = (target - total < sizeof(buffer)) ?
                           (target - total) : sizeof(buffer);
        for (lfs_size_t i = 0; i < chunk; i++) {
            buffer[i] = lfs_ztest_prng(&prng) & 0xff;
        }
        zassert_equal(lfs_file_write(&lfs, &file, buffer, chunk),
                      (lfs_ssize_t)chunk, "Write failed at %u", total);
        total += chunk;
    }
    zassert_equal(lfs_file_close(&lfs, &file), 0, "Close failed");

    /* Verify */
    zassert_equal(lfs_file_open(&lfs, &file, "spill", LFS_O_RDONLY), 0,
                  "Open read failed");
    zassert_equal(lfs_file_size(&lfs, &file), (lfs_soff_t)target, "Size wrong");

    prng = 42;
    total = 0;
    while (total < target) {
        lfs_size_t chunk = (target - total < sizeof(buffer)) ?
                           (target - total) : sizeof(buffer);
        zassert_equal(lfs_file_read(&lfs, &file, buffer, chunk),
                      (lfs_ssize_t)chunk, "Read failed at %u", total);
        for (lfs_size_t i = 0; i < chunk; i++) {
            uint8_t expected = lfs_ztest_prng(&prng) & 0xff;
            zassert_equal(buffer[i], expected, "Mismatch at %u", total + i);
        }
        total += chunk;
    }
    zassert_equal(lfs_file_close(&lfs, &file), 0, "Close failed");

    zassert_equal(lfs_unmount(&lfs), 0, "Unmount failed");
}

/* Test many small files (inline entries) */
ZTEST(entries_tests, test_many_inline)
{
    lfs_t lfs;
    zassert_equal(lfs_format(&lfs, &ztest_cfg), 0, "Format failed");
    zassert_equal(lfs_mount(&lfs, &ztest_cfg), 0, "Mount failed");

    const int N = 10;
    for (int i = 0; i < N; i++) {
        char name[32], data[16];
        snprintf(name, sizeof(name), "inline%d", i);
        snprintf(data, sizeof(data), "d%d", i);

        lfs_file_t file;
        zassert_equal(lfs_file_open(&lfs, &file, name,
                LFS_O_WRONLY | LFS_O_CREAT | LFS_O_EXCL), 0,
                "Open %d failed", i);
        zassert_equal(lfs_file_write(&lfs, &file, data, strlen(data)),
                      (lfs_ssize_t)strlen(data), "Write %d failed", i);
        zassert_equal(lfs_file_close(&lfs, &file), 0, "Close %d failed", i);
    }
    zassert_equal(lfs_unmount(&lfs), 0, "Unmount failed");

    /* Verify */
    zassert_equal(lfs_mount(&lfs, &ztest_cfg), 0, "Remount failed");
    for (int i = 0; i < N; i++) {
        char name[32], expected[16], buffer[16];
        snprintf(name, sizeof(name), "inline%d", i);
        snprintf(expected, sizeof(expected), "d%d", i);

        lfs_file_t file;
        zassert_equal(lfs_file_open(&lfs, &file, name, LFS_O_RDONLY), 0,
                      "Open %d failed", i);
        int len = lfs_file_read(&lfs, &file, buffer, sizeof(buffer));
        zassert_equal(len, (int)strlen(expected), "Read %d size wrong", i);
        buffer[len] = '\0';
        zassert_equal(strcmp(buffer, expected), 0, "Data %d mismatch", i);
        zassert_equal(lfs_file_close(&lfs, &file), 0, "Close %d failed", i);
    }
    zassert_equal(lfs_unmount(&lfs), 0, "Unmount failed");
}
```

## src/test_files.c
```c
/*
 * File operation tests - read/write/append/truncate
 */
#include "lfs_ztest_common.h"
#include <stdio.h>

static void *files_setup(void)
{
    lfs_ztest_format_device();
    return NULL;
}

static void files_before(void *f)
{
    ARG_UNUSED(f);
    lfs_ztest_format_device();
}

ZTEST_SUITE(files_tests, NULL, files_setup, files_before, NULL, NULL);

/* Simple file write and read */
ZTEST(files_tests, test_simple_file)
{
    lfs_t lfs;
    zassert_equal(lfs_format(&lfs, &ztest_cfg), 0, "Format failed");
    zassert_equal(lfs_mount(&lfs, &ztest_cfg), 0, "Mount failed");

    lfs_file_t file;
    zassert_equal(lfs_file_open(&lfs, &file, "hello",
            LFS_O_WRONLY | LFS_O_CREAT | LFS_O_EXCL), 0, "Open failed");

    const char *message = "Hello World!";
    lfs_size_t size = strlen(message) + 1;
    uint8_t buffer[64];
    strcpy((char *)buffer, message);
    zassert_equal(lfs_file_write(&lfs, &file, buffer, size), (lfs_ssize_t)size,
                  "Write failed");
    zassert_equal(lfs_file_close(&lfs, &file), 0, "Close failed");
    zassert_equal(lfs_unmount(&lfs), 0, "Unmount failed");

    /* Remount and read */
    zassert_equal(lfs_mount(&lfs, &ztest_cfg), 0, "Remount failed");
    zassert_equal(lfs_file_open(&lfs, &file, "hello", LFS_O_RDONLY), 0,
                  "Reopen failed");
    zassert_equal(lfs_file_read(&lfs, &file, buffer, size), (lfs_ssize_t)size,
                  "Read failed");
    zassert_equal(strcmp((char *)buffer, message), 0, "Data mismatch");
    zassert_equal(lfs_file_close(&lfs, &file), 0, "Close failed");
    zassert_equal(lfs_unmount(&lfs), 0, "Unmount failed");
}

/* Large file write and read */
ZTEST(files_tests, test_large_file)
{
    lfs_t lfs;
    zassert_equal(lfs_format(&lfs, &ztest_cfg), 0, "Format failed");
    zassert_equal(lfs_mount(&lfs, &ztest_cfg), 0, "Mount failed");

    lfs_file_t file;
    zassert_equal(lfs_file_open(&lfs, &file, "avocado",
            LFS_O_WRONLY | LFS_O_CREAT | LFS_O_EXCL), 0, "Open failed");

    /* Write 8KB of data in chunks */
    lfs_size_t total_size = 8192;
    lfs_size_t chunk_size = 64;
    uint8_t buffer[64];
    uint32_t prng = 1;

    for (lfs_size_t i = 0; i < total_size; i += chunk_size) {
        lfs_size_t chunk = (total_size - i < chunk_size) ? (total_size - i) : chunk_size;
        for (lfs_size_t b = 0; b < chunk; b++) {
            buffer[b] = lfs_ztest_prng(&prng) & 0xff;
        }
        zassert_equal(lfs_file_write(&lfs, &file, buffer, chunk), (lfs_ssize_t)chunk,
                      "Write failed at %u", i);
    }
    zassert_equal(lfs_file_close(&lfs, &file), 0, "Close failed");
    zassert_equal(lfs_unmount(&lfs), 0, "Unmount failed");

    /* Read back and verify */
    zassert_equal(lfs_mount(&lfs, &ztest_cfg), 0, "Remount failed");
    zassert_equal(lfs_file_open(&lfs, &file, "avocado", LFS_O_RDONLY), 0,
                  "Reopen failed");
    zassert_equal(lfs_file_size(&lfs, &file), (lfs_soff_t)total_size,
                  "Size mismatch");

    prng = 1;
    for (lfs_size_t i = 0; i < total_size; i += chunk_size) {
        lfs_size_t chunk = (total_size - i < chunk_size) ? (total_size - i) : chunk_size;
        zassert_equal(lfs_file_read(&lfs, &file, buffer, chunk), (lfs_ssize_t)chunk,
                      "Read failed at %u", i);
        for (lfs_size_t b = 0; b < chunk; b++) {
            uint8_t expected = lfs_ztest_prng(&prng) & 0xff;
            zassert_equal(buffer[b], expected, "Data mismatch at %u", i + b);
        }
    }
    zassert_equal(lfs_file_close(&lfs, &file), 0, "Close failed");
    zassert_equal(lfs_unmount(&lfs), 0, "Unmount failed");
}

/* File append test */
ZTEST(files_tests, test_append)
{
    lfs_t lfs;
    zassert_equal(lfs_format(&lfs, &ztest_cfg), 0, "Format failed");
    zassert_equal(lfs_mount(&lfs, &ztest_cfg), 0, "Mount failed");

    lfs_file_t file;
    /* Initial write */
    zassert_equal(lfs_file_open(&lfs, &file, "appendme",
            LFS_O_WRONLY | LFS_O_CREAT | LFS_O_EXCL), 0, "Open failed");
    zassert_equal(lfs_file_write(&lfs, &file, "hello", 5), 5, "Write1 failed");
    zassert_equal(lfs_file_close(&lfs, &file), 0, "Close failed");

    /* Append */
    zassert_equal(lfs_file_open(&lfs, &file, "appendme",
            LFS_O_WRONLY | LFS_O_APPEND), 0, "Open append failed");
    zassert_equal(lfs_file_write(&lfs, &file, "world", 5), 5, "Write2 failed");
    zassert_equal(lfs_file_close(&lfs, &file), 0, "Close failed");

    /* Read and verify */
    uint8_t buffer[16];
    zassert_equal(lfs_file_open(&lfs, &file, "appendme", LFS_O_RDONLY), 0,
                  "Open read failed");
    zassert_equal(lfs_file_size(&lfs, &file), 10, "Size mismatch");
    zassert_equal(lfs_file_read(&lfs, &file, buffer, 10), 10, "Read failed");
    zassert_equal(memcmp(buffer, "helloworld", 10), 0, "Data mismatch");
    zassert_equal(lfs_file_close(&lfs, &file), 0, "Close failed");

    zassert_equal(lfs_unmount(&lfs), 0, "Unmount failed");
}

/* File truncate test */
ZTEST(files_tests, test_truncate)
{
    lfs_t lfs;
    zassert_equal(lfs_format(&lfs, &ztest_cfg), 0, "Format failed");
    zassert_equal(lfs_mount(&lfs, &ztest_cfg), 0, "Mount failed");

    lfs_file_t file;
    /* Write initial data */
    zassert_equal(lfs_file_open(&lfs, &file, "truncme",
            LFS_O_WRONLY | LFS_O_CREAT | LFS_O_EXCL), 0, "Open failed");
    zassert_equal(lfs_file_write(&lfs, &file, "hello world!", 12), 12,
                  "Write failed");
    zassert_equal(lfs_file_close(&lfs, &file), 0, "Close failed");

    /* Truncate */
    zassert_equal(lfs_file_open(&lfs, &file, "truncme",
            LFS_O_WRONLY | LFS_O_TRUNC), 0, "Open trunc failed");
    zassert_equal(lfs_file_write(&lfs, &file, "hi", 2), 2, "Write2 failed");
    zassert_equal(lfs_file_close(&lfs, &file), 0, "Close failed");

    /* Verify */
    uint8_t buffer[16];
    zassert_equal(lfs_file_open(&lfs, &file, "truncme", LFS_O_RDONLY), 0,
                  "Open read failed");
    zassert_equal(lfs_file_size(&lfs, &file), 2, "Size mismatch");
    zassert_equal(lfs_file_read(&lfs, &file, buffer, 16), 2, "Read failed");
    zassert_equal(memcmp(buffer, "hi", 2), 0, "Data mismatch");
    zassert_equal(lfs_file_close(&lfs, &file), 0, "Close failed");

    zassert_equal(lfs_unmount(&lfs), 0, "Unmount failed");
}

/* Many files test */
ZTEST(files_tests, test_many_files)
{
    lfs_t lfs;
    zassert_equal(lfs_format(&lfs, &ztest_cfg), 0, "Format failed");
    zassert_equal(lfs_mount(&lfs, &ztest_cfg), 0, "Mount failed");

    /* Create multiple files */
    const int N = 10;
    for (int i = 0; i < N; i++) {
        char name[32];
        snprintf(name, sizeof(name), "file%03d", i);
        lfs_file_t file;
        zassert_equal(lfs_file_open(&lfs, &file, name,
                LFS_O_WRONLY | LFS_O_CREAT | LFS_O_EXCL), 0,
                "Open %s failed", name);
        zassert_equal(lfs_file_write(&lfs, &file, name, strlen(name)), (lfs_ssize_t)strlen(name),
                      "Write %s failed", name);
        zassert_equal(lfs_file_close(&lfs, &file), 0, "Close %s failed", name);
    }
    zassert_equal(lfs_unmount(&lfs), 0, "Unmount failed");

    /* Remount and verify */
    zassert_equal(lfs_mount(&lfs, &ztest_cfg), 0, "Remount failed");
    for (int i = 0; i < N; i++) {
        char name[32];
        char buffer[32];
        snprintf(name, sizeof(name), "file%03d", i);
        lfs_file_t file;
        zassert_equal(lfs_file_open(&lfs, &file, name, LFS_O_RDONLY), 0,
                      "Open %s failed", name);
        int len = lfs_file_read(&lfs, &file, buffer, sizeof(buffer));
        zassert_equal(len, (int)strlen(name), "Read %s size mismatch", name);
        buffer[len] = '\0';
        zassert_equal(strcmp(buffer, name), 0, "Data mismatch for %s", name);
        zassert_equal(lfs_file_close(&lfs, &file), 0, "Close %s failed", name);
    }
    zassert_equal(lfs_unmount(&lfs), 0, "Unmount failed");
}

/* Rewrite file test */
ZTEST(files_tests, test_rewrite)
{
    lfs_t lfs;
    zassert_equal(lfs_format(&lfs, &ztest_cfg), 0, "Format failed");
    zassert_equal(lfs_mount(&lfs, &ztest_cfg), 0, "Mount failed");

    lfs_file_t file;
    /* Initial write */
    zassert_equal(lfs_file_open(&lfs, &file, "rewrite",
            LFS_O_WRONLY | LFS_O_CREAT | LFS_O_EXCL), 0, "Open failed");
    zassert_equal(lfs_file_write(&lfs, &file, "original", 8), 8, "Write1 failed");
    zassert_equal(lfs_file_close(&lfs, &file), 0, "Close failed");
    zassert_equal(lfs_unmount(&lfs), 0, "Unmount failed");

    /* Rewrite with different data */
    zassert_equal(lfs_mount(&lfs, &ztest_cfg), 0, "Remount failed");
    zassert_equal(lfs_file_open(&lfs, &file, "rewrite", LFS_O_WRONLY), 0,
                  "Open rewrite failed");
    zassert_equal(lfs_file_write(&lfs, &file, "replaced", 8), 8, "Write2 failed");
    zassert_equal(lfs_file_close(&lfs, &file), 0, "Close failed");

    /* Verify */
    uint8_t buffer[16];
    zassert_equal(lfs_file_open(&lfs, &file, "rewrite", LFS_O_RDONLY), 0,
                  "Open read failed");
    zassert_equal(lfs_file_read(&lfs, &file, buffer, 8), 8, "Read failed");
    zassert_equal(memcmp(buffer, "replaced", 8), 0, "Data mismatch");
    zassert_equal(lfs_file_close(&lfs, &file), 0, "Close failed");

    zassert_equal(lfs_unmount(&lfs), 0, "Unmount failed");
}
```
